# STM32MP13xx register map
File version: 1.5
CPU: CA7 r0p0, little endian, MPU, FPU, 4 interrupt priority bits
Registers are 32-bit, read-write, reset 0x0 unless marked. A register's access mark holds for its fields unless they carry their own. Offsets are from the block's base; [hi:lo] are bit positions; 'fields as' and 'values as' point back to an identical list.

## TIM16
Base 0x4C00B000
Same registers: TIM17 0x4C00C000
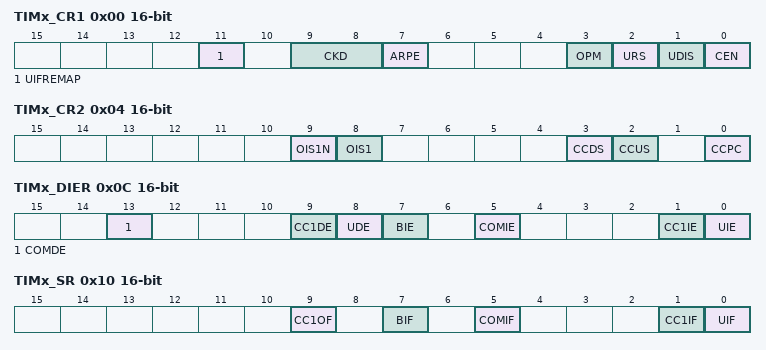
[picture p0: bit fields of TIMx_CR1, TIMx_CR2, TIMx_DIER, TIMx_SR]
0x00 TIMx_CR1 16-bit — TIM16/TIM17 control register 1
  [11] UIFREMAP, [9:8] CKD, [7] ARPE, [3] OPM, [2] URS, [1] UDIS, [0] CEN
0x04 TIMx_CR2 16-bit — TIM16/TIM17 control register 2
  [9] OIS1N, [8] OIS1, [3] CCDS, [2] CCUS, [0] CCPC
0x0C TIMx_DIER 16-bit — TIM16/TIM17 DMA/interrupt enable register
  [13] COMDE, [9] CC1DE, [8] UDE, [7] BIE, [5] COMIE, [1] CC1IE, [0] UIE
0x10 TIMx_SR 16-bit — TIM16/TIM17 status register
  [9] CC1OF, [7] BIF, [5] COMIF, [1] CC1IF, [0] UIF
0x14 TIMx_EGR wo — event generation register
  [0] UG — Update generation
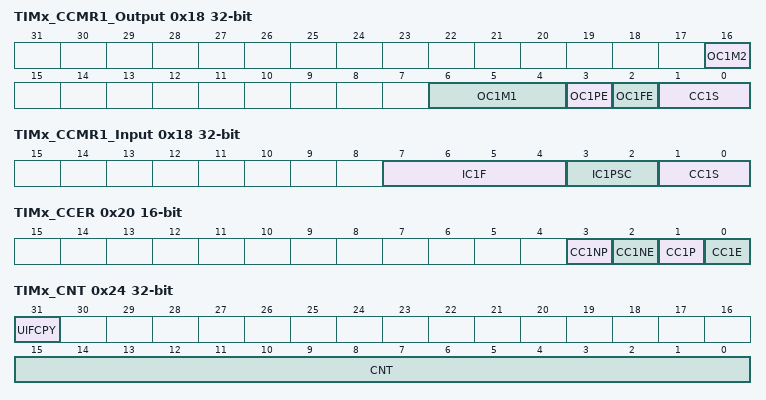
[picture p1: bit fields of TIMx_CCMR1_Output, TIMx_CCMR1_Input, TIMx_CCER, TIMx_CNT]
0x18 TIMx_CCMR1_Output — capture/compare mode register 1 (output mode)
  [16] OC1M2 — Output Compare 1 mode These bits define the behavior of the output reference signal OC1REF from which OC1 and OC1N are derived. OC1REF is active high whereas OC1 and OC1N active level depends on CC1P and CC1NP bits. Note: These bits can not be modified as long as LOCK level 3 has been programmed (LOCK bits in TIMx_BDTR register) and CC1S=â00â (the channel is configured in output). Note: In PWM mode, the OCREF level changes only when the result of the comparison changes or when the output compare mode switches from âfrozenâ mode to âPWMâ mode. Note: On channels having a complementary output, this bit field is preloaded. If the CCPC bit is set in the TIMx_CR2 register then the OC1M active bits take the new value from the preloaded bits only when a COM event is generated. Note: The OC1M[3] bit is not contiguous, located in bit 16.
    0=Frozen - The comparison between the output compare register TIMx_CCR1 and the counter TIMx_CNT has no effect on the outputs.(this mode is used to generate a timing base); 1=Set channel 1 to active level on match. OC1REF signal is forced high when the counter TIMx_CNT matches the capture/compare register 1 (TIMx_CCR1).
  [6:4] OC1M1 — Output Compare 1 mode These bits define the behavior of the output reference signal OC1REF from which OC1 and OC1N are derived. OC1REF is active high whereas OC1 and OC1N active level depends on CC1P and CC1NP bits. Note: These bits can not be modified as long as LOCK level 3 has been programmed (LOCK bits in TIMx_BDTR register) and CC1S=â00â (the channel is configured in output). Note: In PWM mode, the OCREF level changes only when the result of the comparison changes or when the output compare mode switches from âfrozenâ mode to âPWMâ mode. Note: On channels having a complementary output, this bit field is preloaded. If the CCPC bit is set in the TIMx_CR2 register then the OC1M active bits take the new value from the preloaded bits only when a COM event is generated. Note: The OC1M[3] bit is not contiguous, located in bit 16.
  [3] OC1PE — Output Compare 1 preload enable Note: These bits can not be modified as long as LOCK level 3 has been programmed (LOCK bits in TIMx_BDTR register) and CC1S=â00â (the channel is configured in output). The PWM mode can be used without validating the preload register only in one pulse mode (OPM bit set in TIMx_CR1 register). Else the behavior is not guaranteed.
    0=Preload register on TIMx_CCR1 disabled. TIMx_CCR1 can be written at anytime, the new value is taken in account immediately.; 1=Preload register on TIMx_CCR1 enabled. Read/Write operations access the preload register. TIMx_CCR1 preload value is loaded in the active register at each update event.
  [2] OC1FE — Output Compare 1 fast enable This bit decreases the latency between a trigger event and a transition on the timer output. It must be used in one-pulse mode (OPM bit set in TIMx_CR1 register), to have the output pulse starting as soon as possible after the starting trigger.
    0=CC1 behaves normally depending on counter and CCR1 values even when the trigger is ON. The minimum delay to activate CC1 output when an edge occurs on the trigger input is 5 clock cycles.; 1=An active edge on the trigger input acts like a compare match on CC1 output. Then, OC is set to the compare level independently from the result of the comparison. Delay to sample the trigger input and to activate CC1 output is reduced to 3 clock cycles. OCFE acts only if the channel is configured in PWM1 or PWM2 mode.
  [1:0] CC1S — Capture/Compare 1 selection This bit-field defines the direction of the channel (input/output) as well as the used input. Note: CC1S bits are writable only when the channel is OFF (CC1E = '0â in TIMx_CCER).
    0=CC1 channel is configured as output; 1=CC1 channel is configured as input, IC1 is mapped on TI1; 2=CC1 channel is configured as input, IC1 is mapped on TI2; 3=CC1 channel is configured as input, IC1 is mapped on TRC. This mode is working only if an internal trigger input is selected through TS bit (TIMx_SMCR register)
0x18 TIMx_CCMR1_Input (alternate view of TIMx_CCMR1_Output) — capture/compare mode register 1 (input mode)
  [7:4] IC1F — Input capture 1 filter This bit-field defines the frequency used to sample TI1 input and the length of the digital filter applied to TI1. The digital filter is made of an event counter in which N consecutive events are needed to validate a transition on the output:
  [3:2] IC1PSC — Input capture 1 prescaler This bit-field defines the ratio of the prescaler acting on CC1 input (IC1). The prescaler is reset as soon as CC1E=â0â (TIMx_CCER register).
    0=no prescaler, capture is done each time an edge is detected on the capture input; 1=capture is done once every 2 events; 2=capture is done once every 4 events; 3=capture is done once every 8 events
  [1:0] CC1S — Capture/Compare 1 Selection This bit-field defines the direction of the channel (input/output) as well as the used input. Note: CC1S bits are writable only when the channel is OFF (CC1E = '0â in TIMx_CCER).
    values as TIMx_CCMR1_Output.CC1S
0x20 TIMx_CCER 16-bit — TIM16/TIM17 capture/compare enable register
  [3] CC1NP, [2] CC1NE, [1] CC1P, [0] CC1E
0x24 TIMx_CNT — TIM16/TIM17 counter
  [31] UIFCPY ro, [15:0] CNT
0x28 TIMx_PSC 16-bit — TIM16/TIM17 prescaler
0x2C TIMx_ARR 16-bit reset 0xFFFF — TIM16/TIM17 auto-reload register
0x30 TIMx_RCR 16-bit — TIM16/TIM17 repetition counter register
  [7:0] REP
0x34 TIMx_CCR1 16-bit — TIM16/TIM17 capture/compare register 1
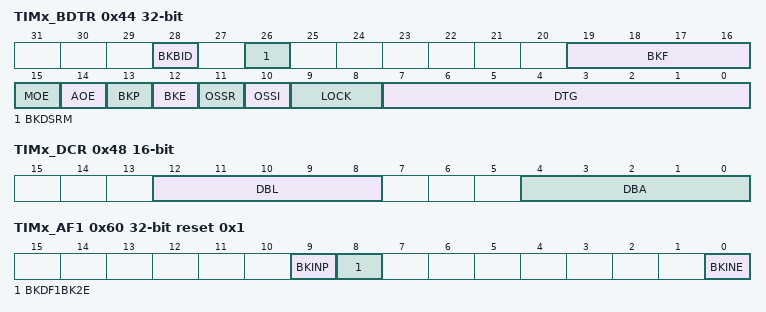
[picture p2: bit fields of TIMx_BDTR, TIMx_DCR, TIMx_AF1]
0x44 TIMx_BDTR — As the BKBID, BKDSRM, BKF[3:0], AOE, BKP, BKE, OSSI, OSSR and DTG[7:0] bits may be write-locked depending on the LOCK configuration, it may be necessary to configure all of them during the first write access to the TIMx_BDTR register.
  [28] BKBID, [26] BKDSRM, [19:16] BKF, [15] MOE, [14] AOE, [13] BKP, [12] BKE, [11] OSSR, [10] OSSI, [9:8] LOCK, [7:0] DTG
0x48 TIMx_DCR 16-bit — TIM16/TIM17 DMA control register
  [12:8] DBL, [4:0] DBA
0x4C TIMx_DMAR 16-bit — TIM16/TIM17 DMA address for full transfer
  [15:0] DMAB
0x60 TIMx_AF1 reset 0x1 — TIM17 alternate function register 1
  [9] BKINP, [8] BKDF1BK2E, [0] BKINE
0x68 TIMx_TISEL — TIM17 input selection register
  [3:0] TI1SEL
